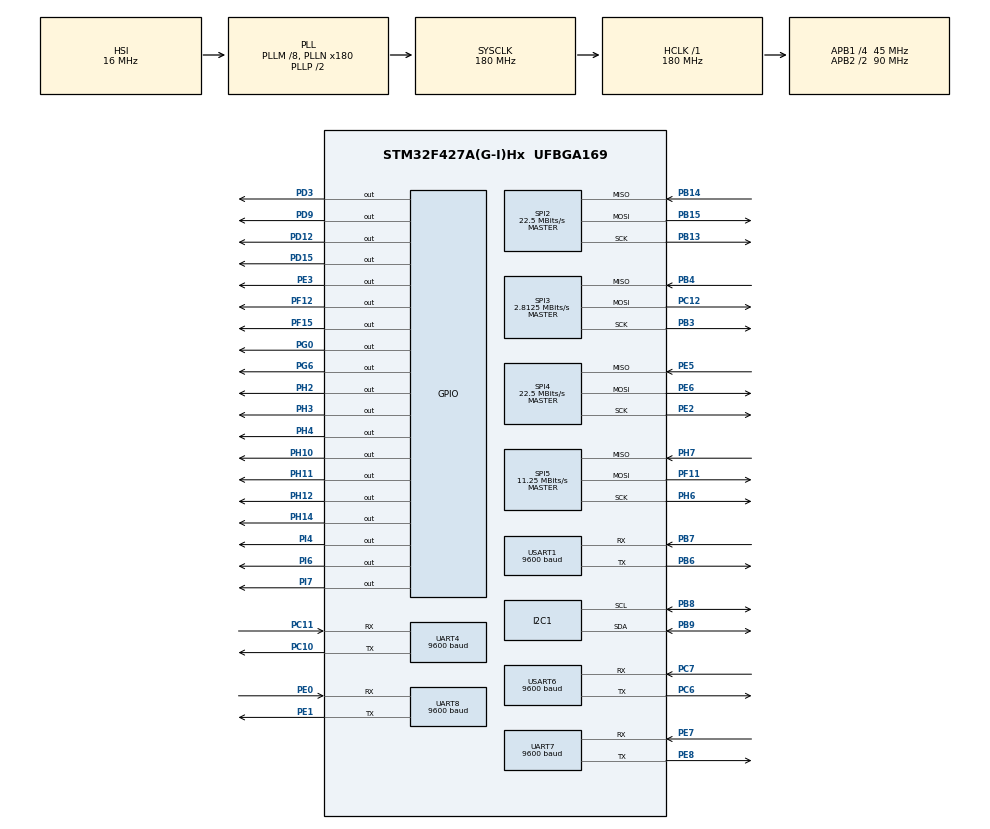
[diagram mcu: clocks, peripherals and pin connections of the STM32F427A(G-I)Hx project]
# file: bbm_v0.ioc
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Mcu.Family=STM32F4
Mcu.Name=STM32F427A(G-I)Hx
Mcu.Package=UFBGA169
NVIC.PriorityGroup=NVIC_PRIORITYGROUP_4
NVIC.RCC_IRQn=true\:0\:0\:false\:false\:true\:true\:false
NVIC.SPI3_IRQn=true\:0\:0\:false\:false\:true\:true\:true
NVIC.SPI5_IRQn=true\:0\:0\:false\:false\:true\:true\:true
NVIC.TIM1_TRG_COM_TIM11_IRQn=true\:0\:0\:false\:false\:true\:true\:true
NVIC.TIM6_DAC_IRQn=true\:0\:0\:false\:false\:true\:true\:true
NVIC.TIM7_IRQn=true\:0\:0\:false\:false\:true\:true\:true
NVIC.UART4_IRQn=true\:0\:0\:false\:false\:true\:true\:true
NVIC.UART7_IRQn=true\:0\:0\:false\:false\:true\:true\:true
NVIC.UART8_IRQn=true\:0\:0\:false\:false\:true\:true\:true
NVIC.USART1_IRQn=true\:0\:0\:false\:false\:true\:true\:true
NVIC.USART6_IRQn=true\:0\:0\:false\:false\:true\:true\:true
PA13.Mode=Serial_Wire
PA13.Signal=SYS_JTMS-SWDIO
PA14.Mode=Serial_Wire
PA14.Signal=SYS_JTCK-SWCLK
PB13.Mode=Full_Duplex_Master
PB13.Signal=SPI2_SCK
PB14.Mode=Full_Duplex_Master
PB14.Signal=SPI2_MISO
PB15.Mode=Full_Duplex_Master
PB15.Signal=SPI2_MOSI
PB3.Mode=Full_Duplex_Master
PB3.Signal=SPI3_SCK
PB4.Mode=Full_Duplex_Master
PB4.Signal=SPI3_MISO
PB6.Mode=Asynchronous
PB6.Signal=USART1_TX
PB7.Mode=Asynchronous
PB7.Signal=USART1_RX
PB8.Mode=I2C
PB8.Signal=I2C1_SCL
PB9.Mode=I2C
PB9.Signal=I2C1_SDA
PC10.Mode=Asynchronous
PC10.Signal=UART4_TX
PC11.Mode=Asynchronous
PC11.Signal=UART4_RX
PC12.Mode=Full_Duplex_Master
PC12.Signal=SPI3_MOSI
PC6.Mode=Asynchronous
PC6.Signal=USART6_TX
PC7.Mode=Asynchronous
PC7.Signal=USART6_RX
PD12.Signal=GPIO_Output
PD15.Signal=GPIO_Output
PD3.Signal=GPIO_Output
PD9.Signal=GPIO_Output
PE0.Mode=Asynchronous
PE0.Signal=UART8_RX
PE1.Mode=Asynchronous
PE1.Signal=UART8_TX
PE2.Mode=Full_Duplex_Master
PE2.Signal=SPI4_SCK
PE3.Signal=GPIO_Output
PE5.Mode=Full_Duplex_Master
PE5.Signal=SPI4_MISO
PE6.Mode=Full_Duplex_Master
PE6.Signal=SPI4_MOSI
PE7.Mode=Asynchronous
PE7.Signal=UART7_RX
PE8.Mode=Asynchronous
PE8.Signal=UART7_TX
PF11.Mode=Full_Duplex_Master
PF11.Signal=SPI5_MOSI
PF12.Signal=GPIO_Output
PF15.Signal=GPIO_Output
PG0.Signal=GPIO_Output
PG6.Signal=GPIO_Output
PH0/OSC_IN.Mode=HSE-External-Oscillator
PH0/OSC_IN.Signal=RCC_OSC_IN
PH1/OSC_OUT.Mode=HSE-External-Oscillator
PH1/OSC_OUT.Signal=RCC_OSC_OUT
PH10.Signal=GPIO_Output
PH11.Signal=GPIO_Output
PH12.Signal=GPIO_Output
PH14.Signal=GPIO_Output
PH2.Signal=GPIO_Output
PH3.Signal=GPIO_Output
PH4.Signal=GPIO_Output
PH6.Mode=Full_Duplex_Master
PH6.Signal=SPI5_SCK
PH7.Mode=Full_Duplex_Master
PH7.Signal=SPI5_MISO
PI4.Signal=GPIO_Output
PI6.Signal=GPIO_Output
PI7.Signal=GPIO_Output
ProjectManager.HeapSize=0x200
ProjectManager.StackSize=0x400
ProjectManager.TargetToolchain=STM32CubeIDE
RCC.48MHZClocksFreq_Value=90000000
RCC.AHBFreq_Value=180000000
RCC.APB1CLKDivider=RCC_HCLK_DIV4
RCC.APB1Freq_Value=45000000
RCC.APB1TimFreq_Value=90000000
RCC.APB2CLKDivider=RCC_HCLK_DIV2
RCC.APB2Freq_Value=90000000
RCC.APB2TimFreq_Value=180000000
RCC.CortexFreq_Value=180000000
RCC.HCLKFreq_Value=180000000
RCC.HSE_VALUE=25000000
RCC.HSI_VALUE=16000000
RCC.LSE_VALUE=32768
RCC.PLLM=8
RCC.PLLN=180
RCC.SYSCLKFreq_VALUE=180000000
RCC.SYSCLKSource=RCC_SYSCLKSOURCE_PLLCLK
RCC.VCOOutputFreq_Value=360000000
SPI2.BaudRatePrescaler=SPI_BAUDRATEPRESCALER_2
SPI2.CalculateBaudRate=22.5 MBits/s
SPI2.Direction=SPI_DIRECTION_2LINES
SPI2.Mode=SPI_MODE_MASTER
SPI2.VirtualType=VM_MASTER
SPI3.BaudRatePrescaler=SPI_BAUDRATEPRESCALER_16
SPI3.CalculateBaudRate=2.8125 MBits/s
SPI3.Direction=SPI_DIRECTION_2LINES
SPI3.Mode=SPI_MODE_MASTER
SPI3.VirtualType=VM_MASTER
SPI4.BaudRatePrescaler=SPI_BAUDRATEPRESCALER_4
SPI4.CalculateBaudRate=22.5 MBits/s
SPI4.Direction=SPI_DIRECTION_2LINES
SPI4.Mode=SPI_MODE_MASTER
SPI4.VirtualType=VM_MASTER
SPI5.BaudRatePrescaler=SPI_BAUDRATEPRESCALER_8
SPI5.CalculateBaudRate=11.25 MBits/s
SPI5.Direction=SPI_DIRECTION_2LINES
SPI5.Mode=SPI_MODE_MASTER
SPI5.VirtualType=VM_MASTER
TIM11.Period=10
TIM11.Prescaler=8400
TIM6.AutoReloadPreload=TIM_AUTORELOAD_PRELOAD_ENABLE
TIM6.Period=1000
TIM6.Prescaler=40
TIM7.AutoReloadPreload=TIM_AUTORELOAD_PRELOAD_ENABLE
TIM7.Period=65535
TIM7.Prescaler=40
UART4.BaudRate=9600
UART4.VirtualMode=Asynchronous
UART7.BaudRate=9600
UART7.VirtualMode=Asynchronous
UART8.BaudRate=9600
UART8.VirtualMode=Asynchronous
USART1.BaudRate=9600
USART1.VirtualMode=VM_ASYNC
USART6.BaudRate=9600
USART6.VirtualMode=VM_ASYNC
VP_TIM11_VS_ClockSourceINT.Mode=Enable_Timer
VP_TIM6_VS_ClockSourceINT.Mode=Enable_Timer
VP_TIM7_VS_ClockSourceINT.Mode=Enable_Timer
board=custom

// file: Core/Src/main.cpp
/* USER CODE BEGIN Header */
/**
  ******************************************************************************
  * @file           : main.c
  * @brief          : Main program body
  ******************************************************************************
  * @attention
  *
  * <h2><center>&copy; Copyright (c) 2024 STMicroelectronics.
  * All rights reserved.</center></h2>
  *
  * This software component is licensed by ST under BSD 3-Clause license,
  * the "License"; You may not use this file except in compliance with the
  * License. You may obtain a copy of the License at:
  *                        opensource.org/licenses/BSD-3-Clause
  *
  ******************************************************************************
  */
/* USER CODE END Header */
#include "main.h"
#include "i2c.h"
#include "spi.h"
#include "tim.h"
#include "usart.h"
#include "gpio.h"

/* USER CODE BEGIN Includes */
//#include "../../Core/user_defined_folder/FLASH_MEMORY/mt25ql.h"
//#include "../../Core/user_defined_folder/IMU/IMU.h"
#include "../../Core/user_defined_folder/EXTERNAL_ADC/ADS79.h"
#include "../../Core/user_defined_folder/MEMORY_ADDRESSING/MEMORYADDRESSING.h"
/* USER CODE END Includes */

/* USER CODE BEGIN PV */
// mt25ql mt;
// IMU imu;
	ADS79 ext;
	  uint8_t counter, count = 0;

 uint8_t pData[] = "OBC working";

 MEMORY_ADDRESSING memory;
/* USER CODE END PV */

void SystemClock_Config(void);

int main(void)
{

  /* MCU Configuration--------------------------------------------------------*/

  /* Reset of all peripherals, Initializes the Flash interface and the Systick. */
  HAL_Init();

  /* USER CODE BEGIN Init */

  memory.get_current_address(&hspi3,0);

  /* USER CODE END Init */

  /* Configure the system clock */
  SystemClock_Config();

  /* Initialize all configured peripherals */
  MX_GPIO_Init();
  MX_SPI3_Init();
  MX_SPI4_Init();
  MX_TIM6_Init();
  MX_TIM7_Init();
  MX_SPI5_Init();
  MX_UART4_Init();
  MX_UART7_Init();
  MX_UART8_Init();
  MX_USART1_UART_Init();
  MX_USART6_UART_Init();
  MX_I2C1_Init();
  MX_TIM11_Init();
  MX_SPI2_Init();
  /* USER CODE BEGIN 2 */

//  mt.Read_ID(&hspi3);
//  imu.IMU_Setup();

  HAL_UART_Transmit(&huart7, (uint8_t*)"S2C OBC Running\n", 17, 1000);
  HAL_TIM_Base_Start(&htim6);
  ext.ADC_Operate();//adc_channels, adc1_channels);
  /* .USER CODE END 2 */

  /* Infinite loop */
  /* USER CODE BEGIN WHILE */
  while (1)
  {
//	  mt.Read_ID(&MAIN_FM_SPI);
//	  imu.HouseKeeping();
//	  HAL_UART_Transmit(&huart4, pData, 9, 1000);
	  counter = __HAL_TIM_GET_COUNTER(&htim6);
	  if( counter - __HAL_TIM_GET_COUNTER(&htim6) > 100000 ){
		  count++;
		  HAL_UART_Transmit(&huart7, (uint8_t*)count, 9, 1000);
		  HAL_UART_Transmit(&huart7, (uint8_t*)"\n", 17, 1000);
	  }
	  HAL_Delay(50);
    /* USER CODE END WHILE */

  }
}

void SystemClock_Config(void)
{
  RCC_OscInitTypeDef RCC_OscInitStruct = {0};
  RCC_ClkInitTypeDef RCC_ClkInitStruct = {0};

  /** Configure the main internal regulator output voltage
  */
  __HAL_RCC_PWR_CLK_ENABLE();
  __HAL_PWR_VOLTAGESCALING_CONFIG(PWR_REGULATOR_VOLTAGE_SCALE1);
  /** Initializes the RCC Oscillators according to the specified parameters
  * in the RCC_OscInitTypeDef structure.
  */
  RCC_OscInitStruct.OscillatorType = RCC_OSCILLATORTYPE_HSI;
  RCC_OscInitStruct.HSIState = RCC_HSI_ON;
  RCC_OscInitStruct.HSICalibrationValue = RCC_HSICALIBRATION_DEFAULT;
  RCC_OscInitStruct.PLL.PLLState = RCC_PLL_ON;
  RCC_OscInitStruct.PLL.PLLSource = RCC_PLLSOURCE_HSI;
  RCC_OscInitStruct.PLL.PLLM = 8;
  RCC_OscInitStruct.PLL.PLLN = 180;
  RCC_OscInitStruct.PLL.PLLP = RCC_PLLP_DIV2;
  RCC_OscInitStruct.PLL.PLLQ = 4;
  if (HAL_RCC_OscConfig(&RCC_OscInitStruct) != HAL_OK)
  {
    Error_Handler();
  }
  /** Activate the Over-Drive mode
  */
  if (HAL_PWREx_EnableOverDrive() != HAL_OK)
  {
    Error_Handler();
  }
  /** Initializes the CPU, AHB and APB buses clocks
  */
  RCC_ClkInitStruct.ClockType = RCC_CLOCKTYPE_HCLK|RCC_CLOCKTYPE_SYSCLK
                              |RCC_CLOCKTYPE_PCLK1|RCC_CLOCKTYPE_PCLK2;
  RCC_ClkInitStruct.SYSCLKSource = RCC_SYSCLKSOURCE_PLLCLK;
  RCC_ClkInitStruct.AHBCLKDivider = RCC_SYSCLK_DIV1;
  RCC_ClkInitStruct.APB1CLKDivider = RCC_HCLK_DIV4;
  RCC_ClkInitStruct.APB2CLKDivider = RCC_HCLK_DIV2;

  if (HAL_RCC_ClockConfig(&RCC_ClkInitStruct, FLASH_LATENCY_5) != HAL_OK)
  {
    Error_Handler();
  }
}

void Error_Handler(void)
{
  __disable_irq();
  while (1)
  {
  }
}

/************************ (C) COPYRIGHT STMicroelectronics *****END OF FILE****/
